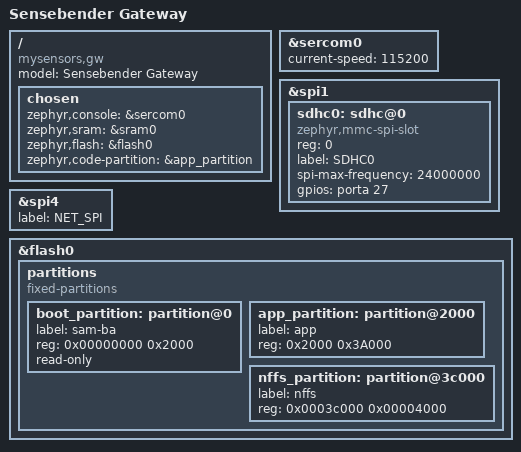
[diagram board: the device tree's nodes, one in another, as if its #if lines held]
/*
 * Copyright (c) 2018 Google LLC.
 *
 * SPDX-License-Identifier: Apache-2.0
 */

/dts-v1/;
#include <atmel/samd21.dtsi>

/ {
	model = "Sensebender Gateway";
	compatible = "mysensors,gw", "atmel,samd21g18a", "atmel,samd21";

	chosen {
		zephyr,console = &sercom0;
		zephyr,sram = &sram0;
		zephyr,flash = &flash0;
		zephyr,code-partition = &app_partition;
	};
};

&sercom0 {
	status = "ok";
	current-speed = <115200>;
};

/* The main SPI port */
&spi1 {
	#address-cells = <1>;
	#size-cells = <0>;
	status = "ok";

	sdhc0: sdhc@0 {
		compatible = "zephyr,mmc-spi-slot";
		reg = <0>;
		status = "ok";
		label = "SDHC0";
		spi-max-frequency = <24000000>;
		gpios = <&porta 27 0>;
	};
};

/* The 'net' SPI port */
&spi4 {
	status = "ok";
	label = "NET_SPI";
};

&flash0 {
	partitions {
		compatible = "fixed-partitions";
		#address-cells = <1>;
		#size-cells = <1>;

		boot_partition: partition@0 {
			label = "sam-ba";
			reg = <0x00000000 0x2000>;
			read-only;
		};

		app_partition: partition@2000 {
			label = "app";
			reg = <0x2000 0x3A000>;
		};

		/*
		 * The final 16 KiB is reserved for the application
		 * and is used by NFFS if enabled.
		 */

#if defined(CONFIG_FILE_SYSTEM_NFFS)
		nffs_partition: partition@3c000 {
			label = "nffs";
			reg = <0x0003c000 0x00004000>;
		};
#endif
	};
};
